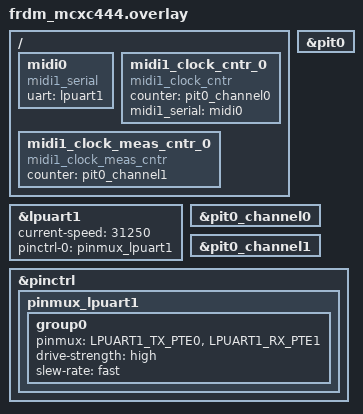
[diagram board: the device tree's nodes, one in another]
/*
 * SPDX-License-Identifier: Apache-2.0
 */

/**
 * @file frdm_mcxc444.overlay
 * @brief Overlay for MIDI 1.0 Hybrid Test on FRDM-MCXC444
 *
 * MIDI Serial: LPUART1 (on mikroBUS pins PTE0/PTE1)
 * MIDI Clock: PIT0 Channel 0
 * MIDI Measurement: PIT0 Channel 1
 */

&lpuart1 {
	status = "okay";
	current-speed = <31250>;
	pinctrl-0 = <&pinmux_lpuart1>;
	pinctrl-names = "default";
};

&pit0 {
	status = "okay";
};

&pit0_channel0 {
	status = "okay";
};

&pit0_channel1 {
	status = "okay";
};

/ {
	midi0: midi0 {
		status = "okay";
		compatible = "midi1_serial";
		uart = <&lpuart1>;
	};

	midi1_clock_cntr_0: midi1_clock_cntr_0 {
		compatible = "midi1_clock_cntr";
		counter = <&pit0_channel0>;
		midi1_serial = <&midi0>;
		status = "okay";
	};

	midi1_clock_meas_cntr_0: midi1_clock_meas_cntr_0 {
		compatible = "midi1_clock_meas_cntr";
		counter = <&pit0_channel1>;
		status = "okay";
	};
};

&pinctrl {
	pinmux_lpuart1: pinmux_lpuart1 {
		group0 {
			pinmux = <LPUART1_TX_PTE0>,
				 <LPUART1_RX_PTE1>;
			drive-strength = "high";
			slew-rate = "fast";
		};
	};
};
